# clcd_reva register map
Registers are access not given, no defined reset value unless marked. A register's access mark holds for its fields unless they carry their own. Offsets are from the block's base; lines under a group give offsets from that group; [hi:lo] are bit positions; {n}, {i} and the like mark numbered series; 'fields as' and 'values as' point back to an identical list; <NAME> marks a mode.

## Memory map
0x40031000 CLCD size 0x1000 — Color LCD Controller

## CLCD — Color LCD Controller
Base 0x40031000
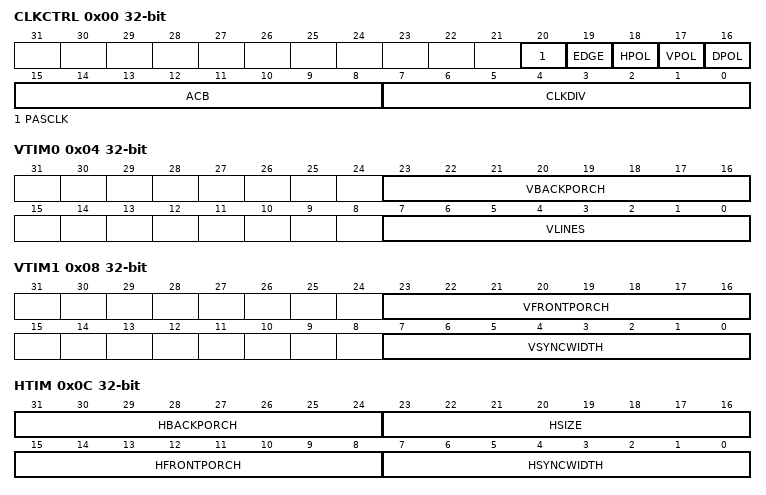
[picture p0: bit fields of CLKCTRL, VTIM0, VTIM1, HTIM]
0x00 CLKCTRL — LCD Clock Control Register
  [20] PASCLK — Clock Active on Data
    0=ALWAYSACTIVE; 1=ACTIVEONDATA
  [19] EDGE — Edge Selection
    0=RISEEDGE (Rising edge); 1=FALLEDGE (Falling Edge)
  [18] HPOL — H Polarity
    1=ACTIVEHI; 0=ACTIVELO (Active Low)
  [17] VPOL — V Polarity
    1=ACTIVEHI; 0=ACTIVELO (Active Low)
  [16] DPOL — D Polarity
    0=ACTIVEHI; 1=ACTIVELO (Active Low)
  [15:8] ACB
  [7:0] CLKDIV — Clock divsor
0x04 VTIM0 — LCD Vertical Timing 0 Register
  [23:16] VBACKPORCH, [7:0] VLINES
0x08 VTIM1 — LCD Vertical Timing 1 Register
  [23:16] VFRONTPORCH, [7:0] VSYNCWIDTH
0x0C HTIM — LCD Horizontal Timing Register.
  [31:24] HBACKPORCH — Horizontal Back Porch size in CLCD Clocks from 1 to 256 -> HBP= (HBACKPORCH+1)
  [23:16] HSIZE — Horizontal Front Porch Size in Pixels = (HSIZE + 1) *16
  [15:8] HFRONTPORCH — Horizontal Front Porch size in lines from 1 to 256
  [7:0] HSYNCWIDTH — Horizontal Sync Width in CLCD Clocks from 1 to 256 HSync Width = HSYNCWIDTH+1 Clocks
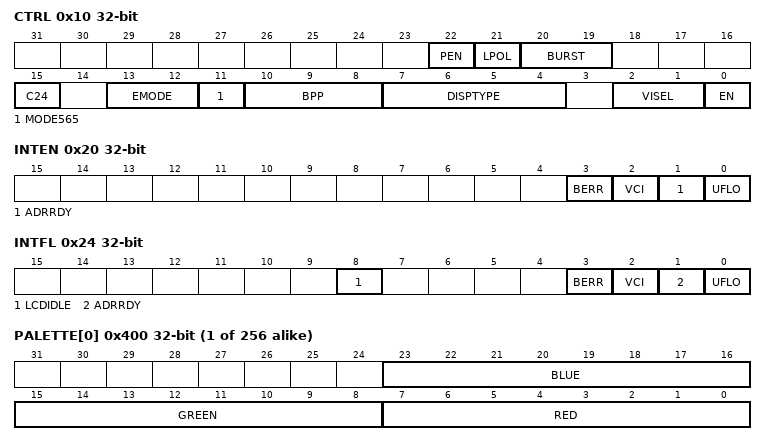
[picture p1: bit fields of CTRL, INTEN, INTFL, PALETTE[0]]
0x10 CTRL — LCD Control Register
  [22] PEN
  [21] LPOL
    0=ACTIVEHI (ACTIVE HIGH); 1=ACTIVELO (ACTIVE LOW)
  [20:19] BURST
    0=WORDS4; 1=WORDS8
  [15] C24
  [13:12] EMODE
    0=LLBP; 1=BBBP; 2=LBBP
  [11] MODE565
    0=BGR556 (MODE 556); 1=RGB565 (MODE 565)
  [10:8] BPP
    0=BPP1; 1=BPP2; 2=BPP4; 3=BPP8; 4=BPP16; 5=BPP24
  [7:4] DISPTYPE — Display Type
    4=STNCOLOR8BIT; 8=CLCD
  [2:1] VISEL — VI Select
    0=ONVERTSYNC (On Vertical Sync); 1=ONVERTBACKPORCH (On Vertical Back Porch); 2=ONACTIVEVIDEO; 3=ONVERTFRONTPORCH (On Vertical Front Porch)
  [0] EN — LCD Enable
    0=DISABLE; 1=ENABLE
{0x18+4i} FRBUF[{i}] (i=0..1) — Frame Buffer Address Register.
  [31:0] ADDR — Frame Buffer Address.
0x20 INTEN — LCD Interrupt Enable Register.
  [3] BERR — BERR Interrupt Enable
  [2] VCI — VCI Interrupt Enable
  [1] ADRRDY — Address Ready Interrupt Enable
  [0] UFLO — Underflow Interrupt Enable
0x24 INTFL write-1-clears — LCD Interrupt Status Register.
  [8] LCDIDLE — LCD IDLE Staus
    0=BUSY; 1=READY
  [3] BERR — BERR Interrupt Status
    on read: 0=Inactive (No interrupt pending); 1=Pending (Interrupt pending) | on write: 1=Clears the interrupt flag
  [2] VCI — VCI Interrupt Status
    values as BERR
  [1] ADRRDY — Address Ready Interrupt Status
    values as BERR
  [0] UFLO — Underflow Interrupt Status
    values as BERR
0x30 HVPHA — LCD PHASE, between HSYNC and VSYNC, Register.
  [7:0] THV — Phase Difference in number of pixel clock.
{0x400+4i} PALETTE[{i}] (i=0..255)
  [23:16] BLUE — Blue Data for Pallet Entry.
  [15:8] GREEN — Green Data for Pallet Entry.
  [7:0] RED — Red Data for Pallet Entry.
